VERSION ""

NS_ :

BS_: 500000

BU_: VCU SteeringWheel

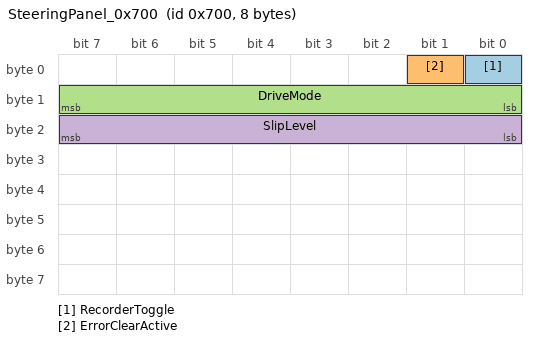
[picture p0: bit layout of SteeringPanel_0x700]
BO_ 1792 SteeringPanel_0x700: 8 SteeringWheel
 SG_ RecorderToggle : 0|1@1+ (1,0) [0|1] "" VCU
 SG_ ErrorClearActive : 1|1@1+ (1,0) [0|1] "" VCU
 SG_ DriveMode : 8|8@1+ (1,0) [0|3] "" VCU
 SG_ SlipLevel : 16|8@1+ (1,0) [0|7] "" VCU

BO_ 1924 DriveMode_0x784: 8 SteeringWheel
 SG_ DriveMode : 0|8@1+ (1,0) [0|3] "" VCU

CM_ BO_ 1792 "Steering wheel unified panel packet — event-driven, sent only on data change";
CM_ SG_ 1792 RecorderToggle "PB12 press: 0=Idle, 1=ToggleRecorderCmd (250ms one-shot pulse)";
CM_ SG_ 1792 ErrorClearActive "PB13 press: 0=Idle, 1=ErrorClear (250ms one-shot pulse)";
CM_ SG_ 1792 DriveMode "Rotary switch S1-S4: 0=S1, 1=S2, 2=S3, 3=S4, 0xFF=Invalid";
CM_ SG_ 1792 SlipLevel "PA1 ADC potentiometer quantized: 0..7 = 8 slip levels";

CM_ BO_ 1924 "Drive mode — existing protocol, sent together with 0x700 on change";
CM_ SG_ 1924 DriveMode "Rotary switch S1-S4: 0=S1, 1=S2, 2=S3, 3=S4, 0xFF=Invalid";

VAL_ 1792 RecorderToggle 0 "Idle" 1 "ToggleRecorder";
VAL_ 1792 ErrorClearActive 0 "Idle" 1 "ErrorClear";
VAL_ 1792 DriveMode 0 "S1" 1 "S2" 2 "S3" 3 "S4" 255 "Invalid";
VAL_ 1792 SlipLevel 0 "Level_0" 1 "Level_1" 2 "Level_2" 3 "Level_3" 4 "Level_4" 5 "Level_5" 6 "Level_6" 7 "Level_7";

VAL_ 1924 DriveMode 0 "S1" 1 "S2" 2 "S3" 3 "S4" 255 "Invalid";

BA_DEF_ "BusType" STRING;
BA_DEF_DEF_ "BusType" "CAN";
